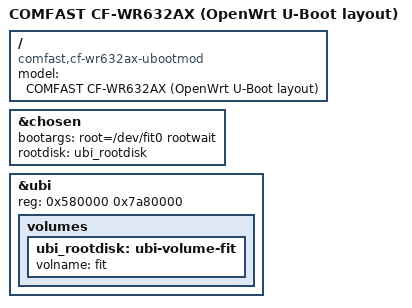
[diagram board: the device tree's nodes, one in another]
// SPDX-License-Identifier: GPL-2.0-or-later OR MIT

#include "mt7981b-comfast-cf-wr632ax-common.dtsi"

/ {
	model = "COMFAST CF-WR632AX (OpenWrt U-Boot layout)";
	compatible = "comfast,cf-wr632ax-ubootmod", "mediatek,mt7981";
};

&chosen {
	bootargs = "root=/dev/fit0 rootwait";
	rootdisk = <&ubi_rootdisk>;
};

&ubi {
	reg = <0x580000 0x7a80000>;

	volumes {
		ubi_rootdisk: ubi-volume-fit {
			volname = "fit";
		};
	};
};
